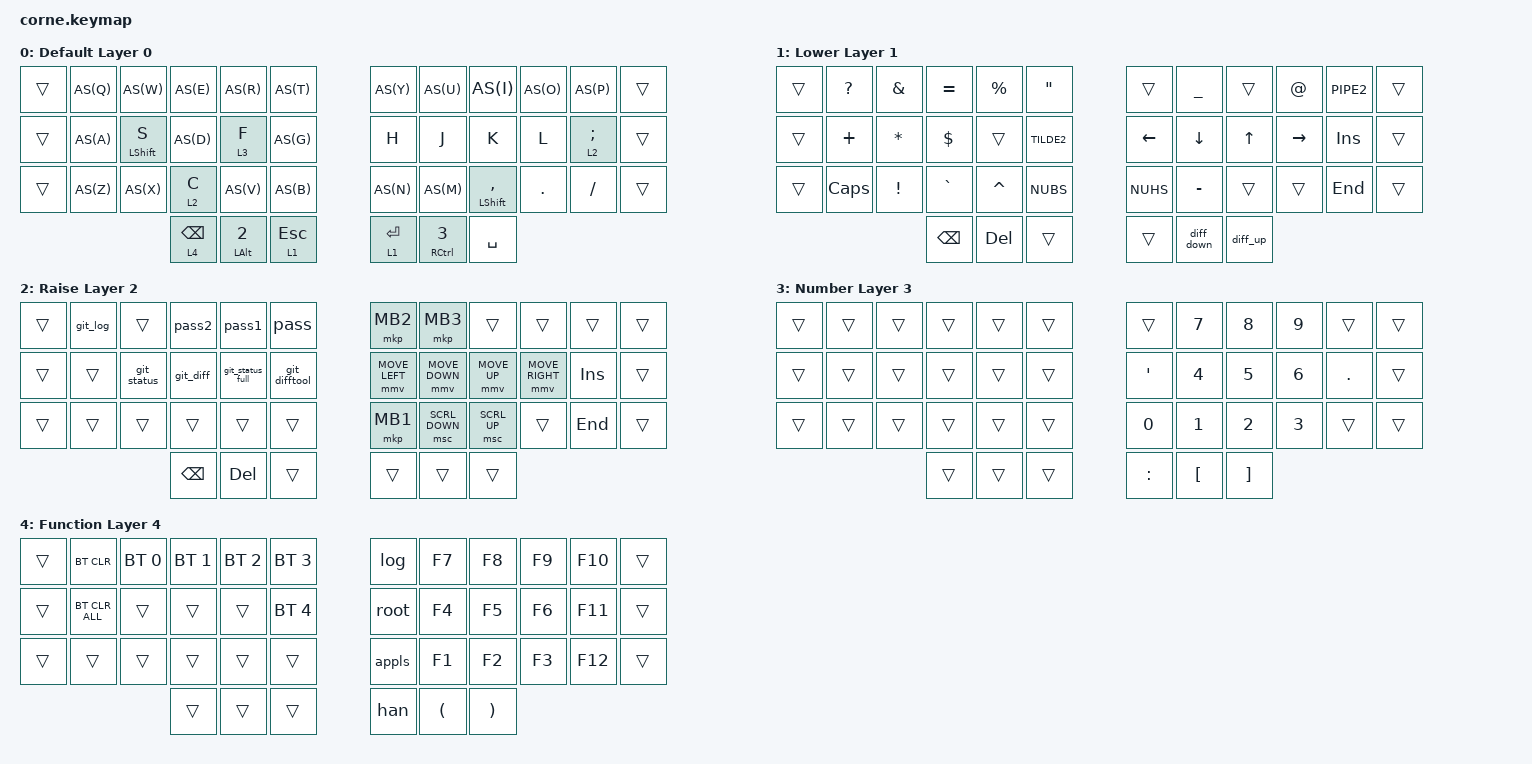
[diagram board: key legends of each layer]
/*
 * Copyright (c) 2020 The ZMK Contributors
 *
 * SPDX-License-Identifier: MIT
 */

#include <behaviors.dtsi>
#include <dt-bindings/zmk/keys.h>
#include <dt-bindings/zmk/bt.h>
#include <dt-bindings/zmk/pointing.h>

#define AS(keycode) &as LS(keycode) keycode

/ {



        keymap {
                compatible = "zmk,keymap";

                default_layer {
                        display-name = "Default Layer 0";
                        bindings = <
   &trans AS(Q) AS(W)        AS(E)    AS(R)    AS(T)          AS(Y) AS(U)  AS(I)             AS(O)   AS(P)      &trans
   &trans AS(A) &mt LSHIFT S AS(D)    &lt 3 F  AS(G)          &kp H &kp J  &kp K             &kp L   &lt 2 SEMI &trans
   &trans AS(Z) AS(X)        &lt 2 C  AS(V)    AS(B)          AS(N) AS(M)  &mt LSHIFT COMMA  &kp DOT &kp FSLH   &trans
                  &lt 4 BSPC &mt LALT N2   &lt 1 ESC      &lt 1 RET    &mt RCTRL N3 &kp SPACE
                        >;
                };
                lower_layer {
                        display-name = "Lower Layer 1";
                        bindings = <
   &trans &kp QMARK &kp AMPS &kp EQUAL &kp PRCNT &kp DQT      &trans    &kp UNDER &trans    &kp AT    &kp PIPE2 &trans 
   &trans &kp PLUS  &kp STAR &kp DLLR  &trans    &kp TILDE2   &kp LEFT  &kp DOWN  &kp UP    &kp RIGHT &kp INS   &trans 
   &trans &kp CAPS  &kp EXCL &kp GRAVE &kp CARET &kp NUBS     &kp NUHS  &kp MINUS &trans    &trans    &kp END   &trans 
                             &kp BSPC  &kp DEL     &trans       &trans    &diff_down &diff_up                           
                        >;
                };

                raise_layer {
                        display-name = "Raise Layer 2";
                        bindings = <
   &trans &git_log &trans      &pass2    &pass1           &pass             &mkp MB2       &mkp MB3       &trans       &trans          &trans   &trans  
   &trans &trans   &git_status &git_diff &git_status_full &git_difftool     &mmv MOVE_LEFT &mmv MOVE_DOWN &mmv MOVE_UP &mmv MOVE_RIGHT &kp INS  &trans  
   &trans &trans   &trans      &trans    &trans           &trans            &mkp MB1       &msc SCRL_DOWN &msc SCRL_UP &trans          &kp END  &trans  
                               &kp BSPC  &kp DEL          &trans            &trans         &trans         &trans                                            
                        >;
                };

                number_layer {
                        display-name = "Number Layer 3";
                        bindings = <
   &trans &trans &trans &trans &trans &trans         &trans    &kp N7   &kp N8 &kp N9 &trans  &trans
   &trans &trans &trans &trans &trans &trans         &kp SQT   &kp N4   &kp N5 &kp N6 &kp DOT &trans
   &trans &trans &trans &trans &trans &trans         &kp N0    &kp N1   &kp N2 &kp N3 &trans &trans
                        &trans &trans &trans         &kp COLON &kp LBKT &kp RBKT
                        >;
                };

                function_layer {
                        display-name = "Function Layer 4";
                        bindings = <
   &trans &bt BT_CLR     &bt BT_SEL 0 &bt BT_SEL 1 &bt BT_SEL 2 &bt BT_SEL 3         &log   &kp F7 &kp F8 &kp F9 &kp F10 &trans
   &trans &bt BT_CLR_ALL &trans       &trans       &trans       &bt BT_SEL 4         &root  &kp F4 &kp F5 &kp F6 &kp F11 &trans
   &trans &trans         &trans       &trans       &trans       &trans               &appls &kp F1 &kp F2 &kp F3 &kp F12 &trans
                        &trans &trans &trans                                     &han   &kp LPAR    &kp RPAR
                        >;
                };
        };
   

    combos {
        compatible = "zmk,combos";

        bt_clear {
            timeout-ms = <50>;
            key-positions = <20 21>;
            bindings = <&bt BT_CLR>;
        };

        combo_tab {
            timeout-ms = <50>;
            key-positions = <19 20>;
            bindings = <&kp TAB>;
        };

        combo_gui {
            timeout-ms = <50>;
            key-positions = <18 19>;         // E + R
            bindings = <&kp LGUI>;
        };
    };

      behaviors {
            as: auto_shift {
                compatible = "zmk,behavior-hold-tap";
                #binding-cells = <2>;
                tapping_term_ms = <200>;
                quick_tap_ms = <0>;
                flavor = "tap-preferred";
                bindings = <&kp>, <&kp>;
            };

            root: root {
                compatible = "zmk,behavior-macro";
                #binding-cells = <0>;
                bindings = <&macro_tap &kp R &kp O &kp O &kp T &kp RET>;
            };

            appls: appls {
                compatible = "zmk,behavior-macro";
                #binding-cells = <0>;
                bindings = <&macro_tap &kp LS(A) &kp P &kp P &kp E &kp L &kp S &kp LS(O) &kp R &kp A &kp N &kp J &kp E &kp S &kp RET>;
            };

            han: han {
                compatible = "zmk,behavior-macro";
                #binding-cells = <0>;
                bindings = <&macro_tap &kp LS(H) &kp A &kp N &kp LS(C) &kp O &kp M &kp M &kp S &kp LS(M) &kp A &kp N &kp A &kp G &kp E &kp R &kp LS(C) &kp L &kp I &kp SPACE &kp G &kp E &kp T &kp MINUS &kp S &kp T &kp A &kp T &kp U &kp S &kp RET>;
            };
            
            pass: pass {
                compatible = "zmk,behavior-macro";
                #binding-cells = <0>;
                bindings = <&macro_tap &kp M &kp A &kp R &kp N0 &kp N4 &kp B &kp I &kp R &kp RET>;
            };

            pass1: pass1 {
                compatible = "zmk,behavior-macro";
                #binding-cells = <0>;
                bindings = <&macro_tap &kp LS(M) &kp A &kp R &kp N0 &kp N4 &kp B &kp I &kp R &kp RET>;
            };

            pass2: pass2 {
                compatible = "zmk,behavior-macro";
                #binding-cells = <0>;
                bindings = <&macro_tap &kp B &kp E &kp L &kp L &kp A &kp UNDER &kp T &kp H &kp E &kp UNDER &kp B &kp U &kp N &kp N &kp Y &kp RET>;
            };

            log: log {
                compatible = "zmk,behavior-macro";
                #binding-cells = <0>;
                bindings = <&macro_tap &kp T &kp A &kp I &kp L &kp SPACE &kp MINUS &kp LS(F) &kp SPACE &kp SLASH &kp V &kp A &kp R &kp SLASH &kp L &kp O &kp G &kp SLASH &kp L &kp O &kp G &kp F &kp I &kp L &kp E &kp N1 &kp DOT &kp T &kp X &kp T &kp SPACE>;
            };

            diff_down: diff_down {
                compatible = "zmk,behavior-macro";
                #binding-cells = <0>;
                bindings = <&macro_tap &kp RBKT &kp C>;
            };

            diff_up: diff_up {
                compatible = "zmk,behavior-macro";
                #binding-cells = <0>;
                bindings = <&macro_tap &kp LBKT &kp C>;
            };

            git_status: git_status {
                compatible = "zmk,behavior-macro";
                #binding-cells = <0>;
                bindings = <&macro_tap &kp G &kp I &kp T &kp SPACE &kp S &kp T &kp A &kp T &kp U &kp S &kp SPACE &kp MINUS &kp U &kp N &kp O &kp SPACE &kp DOT &kp RET>;
            };

            git_status_full: git_status_full {
                compatible = "zmk,behavior-macro";
                #binding-cells = <0>;
                bindings = <&macro_tap &kp G &kp I &kp T &kp SPACE &kp S &kp T &kp A &kp T &kp U &kp S &kp SPACE &kp DOT &kp RET>;
            };

//        SEND_STRING("git diff .\n");
            git_diff: git_diff {
                compatible = "zmk,behavior-macro";
                #binding-cells = <0>;
                bindings = <&macro_tap &kp G &kp I &kp T &kp SPACE &kp D &kp I &kp F &kp F &kp SPACE &kp DOT &kp RET>;
            };
//        SEND_STRING("git log --pretty=format:\"%h%x09%an%x09%ad%x09%s\"\n");
//                git log --pretty=format:@%h_%an_%ad_%s@
//            git_log: git_log {
//                compatible = "zmk,behavior-macro";
//                #binding-cells = <0>;
//                bindings = <&macro_tap &kp G &kp I &kp T &kp SPACE &kp L &kp O &kp G &kp SPACE &kp MINUS &kp MINUS &kp P &kp R &kp E &kp T &kp T &kp Y &kp EQUAL &kp F &kp O &kp R &kp M &kp A &kp T &kp COLON &kp DQT &kp PRCNT &kp H &kp UNDER &kp PRCNT &kp A &kp N &kp UNDER &kp PRCNT &kp A &kp D &kp UNDER &kp PRCNT &kp S &kp DQT &kp RET>;
//            };
            git_log: git_log {
                compatible = "zmk,behavior-macro";
                #binding-cells = <0>;
                bindings = <&macro_tap &kp Q &kp RET>;
            };
//        SEND_STRING("git log --pretty=format:\"%h%x09%an%x09%ad%x09%s\"\n");
            git_difftool: git_difftool {
                compatible = "zmk,behavior-macro";
                #binding-cells = <0>;
                bindings = <&macro_tap &kp G &kp I &kp T &kp SPACE &kp D &kp I &kp F &kp F &kp T &kp O &kp O &kp L &kp SPACE &kp DOT &kp RET>;
            };

            git_branch: git_branch {
                compatible = "zmk,behavior-macro";
                #binding-cells = <0>;
                bindings = <&macro_tap &kp G &kp I &kp T &kp SPACE &kp B &kp R &kp A &kp N &kp C &kp H &kp RET>;
            };

        };

};
